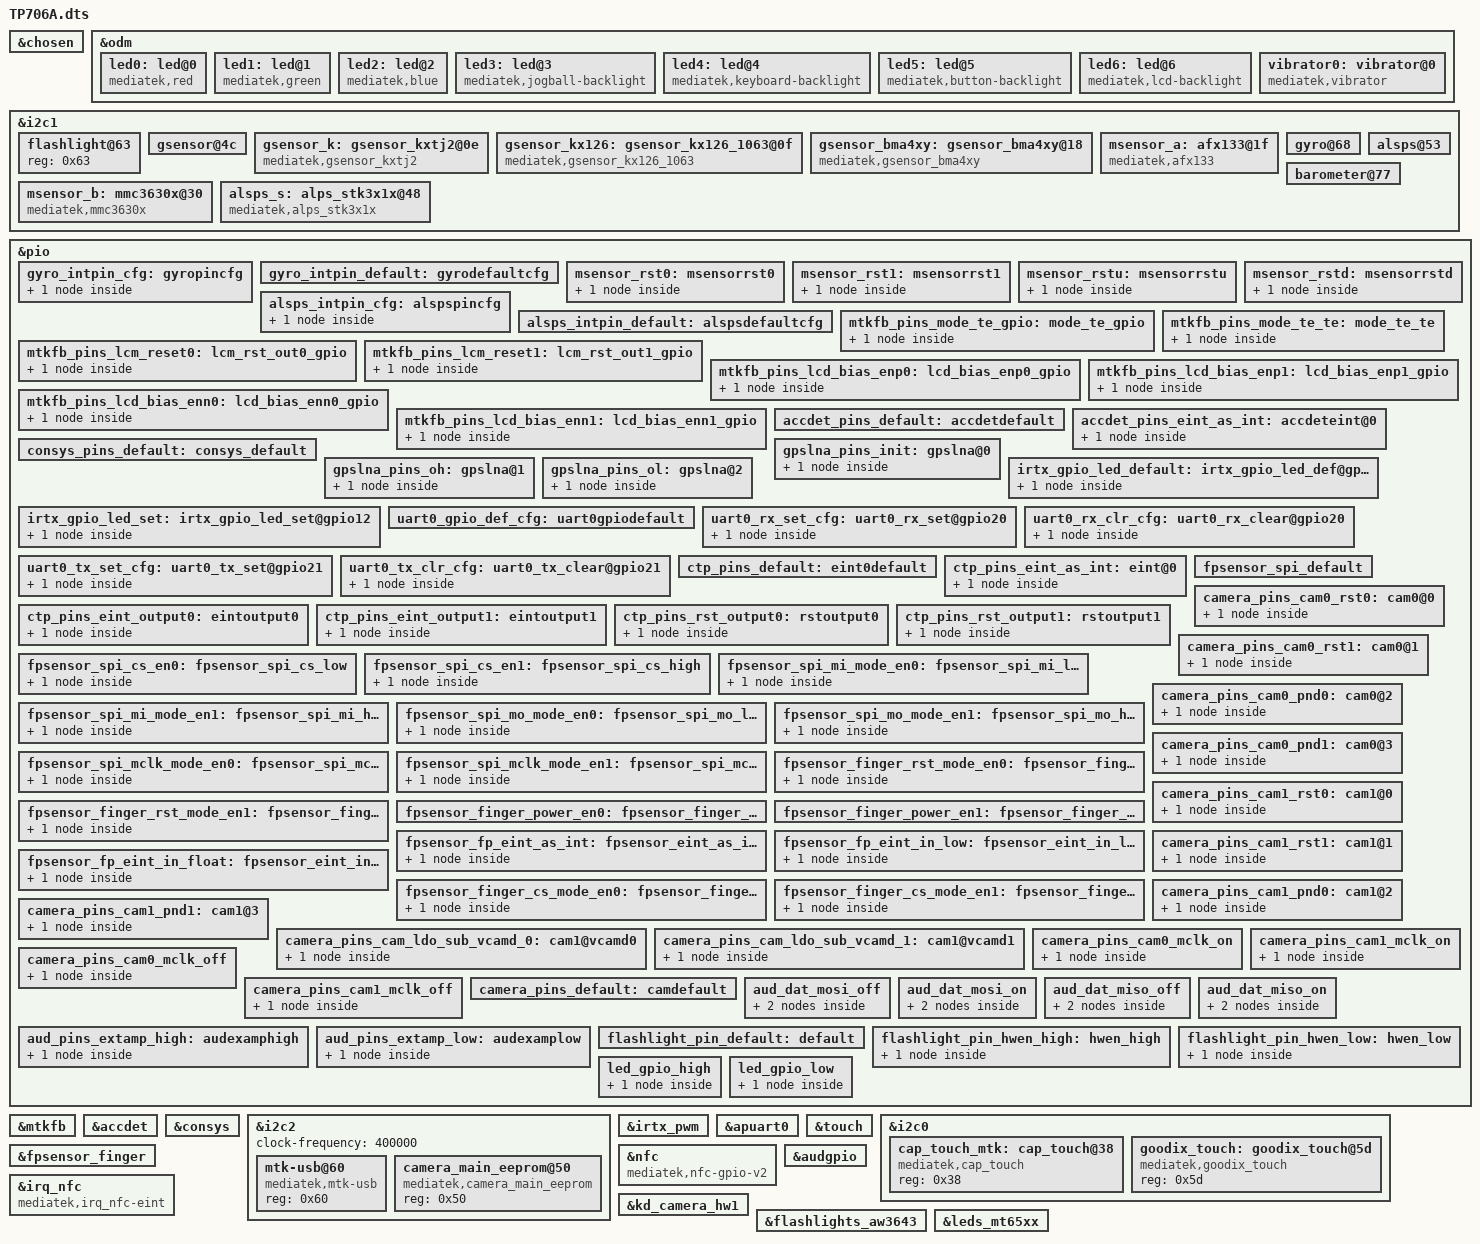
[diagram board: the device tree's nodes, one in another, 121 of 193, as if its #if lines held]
#include <generated/autoconf.h>
/dts-v1/;

#ifdef CONFIG_MTK_DTBO_FEATURE
/plugin/;
#include <dt-bindings/mmc/mt6739-msdc.h>
#include <dt-bindings/pinctrl/mt6739-pinfunc.h>
#else
#include "mt6739.dts"
#endif

#include <dt-bindings/interrupt-controller/irq.h>
#include <dt-bindings/interrupt-controller/arm-gic.h>

/*add by chipsailing*/
//#include "chips.dtsi"
#include "ChipSailing_pin.dtsi"
/*add end*/
/* chosen */
&chosen {
	bootargs = "console=tty0 console=ttyMT0,921600n1 root=/dev/ram initrd=0x44000000,\
0x1000000 loglevel=8 androidboot.selinux=permissive androidboot.hardware=mt6739 initcall_debug=1";
	/* fpga may has no lk, we need to specify display info here */
	/* fb buffer is reserved using this dts by memory node above */

	atag,videolfb-fb_base_l = <0x5e605000>;
	atag,videolfb-fb_base_h = <0>;
	atag,videolfb-islcmfound = <1>;
	atag,videolfb-islcm_inited = <0>;
	atag,videolfb-fps= <6000>;
	atag,videolfb-vramSize= <0x017bb000>;
	   atag,videolfb-lcmname= "ontim_ft8006u";	
/*atag,videolfb-lcmname= "txd_ili9881c";*/

};

&odm {
	led0:led@0 {
		compatible = "mediatek,red";
		led_mode = <2>;
		data = <1>;
		pwm_config = <0 0 0 0 0>;
	};
	led1:led@1 {
		compatible = "mediatek,green";
		led_mode = <3>;
		data = <2>;
		pwm_config = <0 0 0 0 0>;
	};
	led2:led@2 {
		compatible = "mediatek,blue";
		led_mode = <0>;
		data = <1>;
		pwm_config = <0 0 0 0 0>;
	};
	led3:led@3 {
		compatible = "mediatek,jogball-backlight";
		led_mode = <0>;
		data = <1>;
		pwm_config = <0 0 0 0 0>;
	};
	led4:led@4 {
		compatible = "mediatek,keyboard-backlight";
		led_mode = <0>;
		data = <1>;
		pwm_config = <0 0 0 0 0>;
	};
	led5:led@5 {
		compatible = "mediatek,button-backlight";
		led_mode = <0>;
		data = <1>;
		pwm_config = <0 0 0 0 0>;
	};
	led6:led@6 {
		compatible = "mediatek,lcd-backlight";
		led_mode = <4>;
		data = <1>;
		pwm_config = <0 2 0 0 0>;
	};
	vibrator0:vibrator@0 {
		compatible = "mediatek,vibrator";
		vib_timer = <25>;
		vib_limit = <9>;
		vib_vol= <9>;
	};
};

&i2c1 {
	flashlight@63 {
		reg = <0x63>;
		status = "okay";
	};

/*  start sensor */
	gsensor@4c {
		i2c_num	= <1>;
		i2c_addr = <0x4c 0 0 0>;
		direction = <6>;
		power_id = <0xffff>;
		power_vol = <0>;
		firlen = <16>;
		is_batch_supported = <1>;
	};

	gsensor_k:gsensor_kxtj2@0e {
		compatible = "mediatek,gsensor_kxtj2";
		reg = <0x0e>;
		status = "okay";
		
		i2c_num	= <1>;
		i2c_addr = <0x0e 0 0 0>;
		direction = <6>;
		power_id = <0xffff>;
		power_vol = <0>;
		firlen = <16>;
		is_batch_supported = <1>;
	};
	gsensor_kx126:gsensor_kx126_1063@0f {
		compatible = "mediatek,gsensor_kx126_1063";
		reg = <0x0f>;
		status = "okay";
		
		i2c_num	= <1>;
		i2c_addr = <0x0f 0 0 0>;
		direction = <6>;
		power_id = <0xffff>;
		power_vol = <0>;
		firlen = <16>;
		is_batch_supported = <1>;
	};
	gsensor_bma4xy:gsensor_bma4xy@18 {
		compatible = "mediatek,gsensor_bma4xy";
		reg = <0x18>;
		status = "okay";
		
		i2c_num	= <1>;
		i2c_addr = <0x18 0 0 0>;
		direction = <6>;
		power_id = <0xffff>;
		power_vol = <0>;
		firlen = <16>;
		is_batch_supported = <1>;
	};

	msensor_a:afx133@1f{
		compatible = "mediatek,afx133";
		reg = <0x1f>;
		i2c_num = <1>;
		i2c_addr = <0x1f 0x1d 0 0>;
		direction = <7>;
		power_id = <0xffff>;
		power_vol = <0>;
		is_batch_supported = <0>;
		pinctrl-names = "msensor_rst_out0", "msensor_rst_out1", "msensor_rst_in_pu", "msensor_rst_in_pd";
		pinctrl-0 = <&msensor_rst0>;
		pinctrl-1 = <&msensor_rst1>;
		pinctrl-2 = <&msensor_rstu>;
		pinctrl-3 = <&msensor_rstd>;
		status = "okay";
	};

	msensor_b:mmc3630x@30 {
		compatible = "mediatek,mmc3630x";
		reg = <0x30>;
		i2c_num = <1>;
		i2c_addr = <0x30 0 0 0>;
		direction = <7>;
		power_id = <0xffff>;
		power_vol = <0>;
		is_batch_supported = <0>;
		pinctrl-names = "msensor_rst_out0", "msensor_rst_out1", "msensor_rst_in_pu", "msensor_rst_in_pd";
		pinctrl-0 = <&msensor_rst0>;
		pinctrl-1 = <&msensor_rst1>;
		pinctrl-2 = <&msensor_rstu>;
		pinctrl-3 = <&msensor_rstd>;
		status = "okay";
	};

	gyro@68 {
		pinctrl-names = "pin_default", "pin_cfg";
		pinctrl-0 = <&gyro_intpin_default>;
		pinctrl-1 = <&gyro_intpin_cfg>;
		i2c_num = <1>;
		i2c_addr = <0x68 0 0 0>;
		direction = <5>;
		power_id = <0xffff>;
		power_vol = <0>;
		firlen = <0>;
		is_batch_supported = <0>;
	};

	alsps@53 {
		pinctrl-names = "pin_default", "pin_cfg";
		pinctrl-0 = <&alsps_intpin_default>;
		pinctrl-1 = <&alsps_intpin_cfg>;
		status = "okay";
		/* customization */

                /*compatible                              = "mediatek,ltr578";*/
		i2c_num = <1>;
              i2c_addr                                = <0x53 0 0 0>;
		polling_mode_ps = <0>;
		polling_mode_als = <1>;
		power_id = <0xffff>;
		power_vol = <0>;
                als_level = <
                                        0  119  275  455  896  1507  2116    2661
                                        0  133  304   502  1004  2005  3058 4000
                                        0  133  304   502  1004  2005  3058 4000
                                        0  85  194  320  630  1059  1667    2210
                                        0  133  304   502  1004  2005  3058 4000
                                        0  133  304   502  1004  2005  3058 4000
                                         >;
                als_value = < 0  133  304  502   1004  2005  3058   4000 >;
                ps_threshold_high               =  <1000>;
                ps_threshold_low                =  <800>;
		is_batch_supported_ps = <0>;
		is_batch_supported_als = <0>;
		/*
		als_calib_enable = <1>;
                als_ch0_expect               =  <1000>;
                als_ch1_expect                =  <800>;
		*/
	};

	alsps_s:alps_stk3x1x@48 {
		compatible				= "mediatek,alps_stk3x1x";
		reg = <0x48>;
		status = "okay";

		pinctrl-names = "pin_default", "pin_cfg";
		pinctrl-0 = <&alsps_intpin_default>;
		pinctrl-1 = <&alsps_intpin_cfg>;

		interrupt-parent = <&pio>;
		interrupts = <1 IRQ_TYPE_LEVEL_LOW 1 0>;

		i2c_num				= <1>;
		i2c_addr				= <0x48 0 0 0>;
		polling_mode_ps			= <0>;
		polling_mode_als		= <1>;
		power_id				= <0xffff>;
		power_vol				= <0>;
		als_level = < 
					0  39   91    150    290    505     736    943
					0  82   174   299    582    1319    2940  3333
					0  123   264   399    627    1444   2144   2800
					0  63   144    237    445    724     991    1231
					0  72   163   258    560    1576   2400   3152
					0  112   240   475    746    1719   2552   3333
					  >;
		als_value = < 0  133  304  502   1004  2005  3058   4000 >;
		state_val		=  <0>;
		psctrl_val		=  <0x31>;
		alsctrl_val	= <0x38>;
		ledctrl_val	= <0xFF>;
		wait_val		= <0xF>;
		ps_threshold_high		=  <1700>;
		ps_threshold_low		=  <1500>;
		is_batch_supported_ps	= <0>;
		is_batch_supported_als	= <0>;
		/*
                als_calib_enable = <1>;
                als_ch0_expect               =  <1000>;
                als_ch1_expect                =  <800>;
                */
		};

	barometer@77 {
		i2c_num = <1>;
		i2c_addr = <0x77 0 0 0>;
		direction = <0>;
		power_id = <0xffff>;
		power_vol = <0>;
		firlen = <32>;
		is_batch_supported = <0>;
	};
/* end sensor */
};

/* sensor gpio standization */
&pio {

	gyro_intpin_cfg: gyropincfg {

	    pins_cmd_dat {
			pins = <PINMUX_GPIO5__FUNC_GPIO5>;
			slew-rate = <0>;
			bias-pull-down = <00>;
		};
	};

	gyro_intpin_default: gyrodefaultcfg {

	};
};
&pio {

	msensor_rst0: msensorrst0 {
	    pins_cmd_dat {
			pins = <PINMUX_GPIO26__FUNC_GPIO26>;
			slew-rate = <1>;
			output-low;
		};
	};

	msensor_rst1: msensorrst1 {
	    pins_cmd_dat {
			pins = <PINMUX_GPIO26__FUNC_GPIO26>;
			slew-rate = <1>;
			output-high;
		};
	};

	msensor_rstu: msensorrstu {
	    pins_cmd_dat {
			pins = <PINMUX_GPIO26__FUNC_GPIO26>;
			slew-rate = <0>;
			bias-pull-up = <00>;
		};
	};

	msensor_rstd: msensorrstd {
	    pins_cmd_dat {
			pins = <PINMUX_GPIO26__FUNC_GPIO26>;
			slew-rate = <0>;
			bias-pull-down = <00>;
		};
	};

};

&pio {
	alsps_intpin_cfg: alspspincfg {

		pins_cmd_dat {
			pins = <PINMUX_GPIO1__FUNC_GPIO1>;
			slew-rate = <0>;
			bias-pull-up = <MTK_PUPD_SET_R1R0_01>;
		};
	};

	alsps_intpin_default: alspsdefaultcfg {

	};
};

/* sensor end */

/* DISPSYS GPIO standardization */
&pio {
	mtkfb_pins_mode_te_gpio: mode_te_gpio {
		pins_cmd_dat {
			pins = <PINMUX_GPIO84__FUNC_DSI_TE>;
		};
	};

	mtkfb_pins_mode_te_te: mode_te_te {
		pins_cmd_dat {
			pins = <PINMUX_GPIO84__FUNC_DSI_TE>;
		};
	};

	mtkfb_pins_lcm_reset0: lcm_rst_out0_gpio {
		pins_cmd_dat {
			pins = <PINMUX_GPIO83__FUNC_GPIO83>;
			slew-rate = <1>;
			output-low;
		};
	};

	mtkfb_pins_lcm_reset1: lcm_rst_out1_gpio {
		pins_cmd_dat {
			pins = <PINMUX_GPIO83__FUNC_GPIO83>;
			slew-rate = <1>;
			output-high;
		};
	};

	mtkfb_pins_lcd_bias_enp0: lcd_bias_enp0_gpio {
		pins_cmd_dat {
			pins = <PINMUX_GPIO122__FUNC_GPIO122>;
			slew-rate = <1>;
			output-low;
		};
	};
	mtkfb_pins_lcd_bias_enp1: lcd_bias_enp1_gpio {
		pins_cmd_dat {
			pins = <PINMUX_GPIO122__FUNC_GPIO122>;
			slew-rate = <1>;
			output-high;
		};
	};

	mtkfb_pins_lcd_bias_enn0: lcd_bias_enn0_gpio {
		pins_cmd_dat {
			pins = <PINMUX_GPIO112__FUNC_GPIO112>;
			slew-rate = <1>;
			output-low;
		};
	};
	mtkfb_pins_lcd_bias_enn1: lcd_bias_enn1_gpio {
		pins_cmd_dat {
			pins = <PINMUX_GPIO112__FUNC_GPIO112>;
			slew-rate = <1>;
			output-high;
		};
	};

};

&mtkfb {
	pinctrl-names = "mode_te_gpio", "mode_te_te", "lcm_rst_out0_gpio",
		"lcm_rst_out1_gpio", "lcd_bias_enp0_gpio", "lcd_bias_enp1_gpio", "lcd_bias_enn0_gpio", "lcd_bias_enn1_gpio";
	pinctrl-0 = <&mtkfb_pins_mode_te_gpio>;
	pinctrl-1 = <&mtkfb_pins_mode_te_te>;
	pinctrl-2 = <&mtkfb_pins_lcm_reset0>;
	pinctrl-3 = <&mtkfb_pins_lcm_reset1>;
	pinctrl-4 = <&mtkfb_pins_lcd_bias_enp0>;
	pinctrl-5 = <&mtkfb_pins_lcd_bias_enp1>;
	pinctrl-6 = <&mtkfb_pins_lcd_bias_enn0>;
	pinctrl-7 = <&mtkfb_pins_lcd_bias_enn1>;
	status = "okay";
};
/* DISPSYS GPIO standardization end */


/* accdet start */
&accdet {
	/* accdet micbias voltage: 0x07,2.7v;0x05,2.5v;0x02,1.9v */
	accdet-mic-vol = <6>;
	headset-mode-setting = <0x500 0x500 1 0x1f0 0x800 0x800 0x20 0x44>;
	accdet-plugout-debounce = <1>;
	/*1:ACC mode, 2:low cost without in bias, 6:low cost with in bias*/
    /* [wuhefeng] change mic-mode to 1(ACC MODE) */
	accdet-mic-mode = <1>;
	/* eint_level_trigger: 8,LEVEL_LOW(default);4,LEVEL_HIGH;others,LEVEL_LOW */
	headset-eint-level-pol = <8>;
	/*0--MD_MAX--UP_MAX--DW_MAX*/
	headset-three-key-threshold = <0 80 220 400>;
	headset-three-key-threshold-CDD = <0 121 192 600>;
	/*0--MD_MAX--VOICE_MAX--UP_MAX--DW_MAX*/
	headset-four-key-threshold = <0 58 121 192 400>;
	/* ACCDET GPIO standardization ACC mode no use */
	pinctrl-names = "default", "state_eint_as_int";
	pinctrl-0 = <&accdet_pins_default>;
	pinctrl-1 = <&accdet_pins_eint_as_int>;
	status = "okay";
};
&pio {
	accdet_pins_default: accdetdefault {
	};
	accdet_pins_eint_as_int: accdeteint@0 {
		pins_cmd_dat {
			/*pins = <PINMUX_GPIO11__FUNC_GPIO11>;*/
			slew-rate = <0>;
			bias-disable;
		};
	};
};
/* accdet end */
/* CONSYS GPIO standardization */
&pio {
	consys_pins_default: consys_default {
	};
	gpslna_pins_init: gpslna@0 {
		pins_cmd_dat {
			pins = <PINMUX_GPIO118__FUNC_GPIO118>;
			slew-rate = <0>;
			bias-disable;
			output-low;
		};
	};
	gpslna_pins_oh: gpslna@1 {
		pins_cmd_dat {
			pins = <PINMUX_GPIO118__FUNC_GPIO118>;
			slew-rate = <1>;
			output-high;
		};
	};
	gpslna_pins_ol: gpslna@2 {
		pins_cmd_dat {
			pins = <PINMUX_GPIO118__FUNC_GPIO118>;
			slew-rate = <1>;
			output-low;
		};
	};
};
&consys {
	pinctrl-names = "default", "gps_lna_state_init", "gps_lna_state_oh", "gps_lna_state_ol";
	pinctrl-0 = <&consys_pins_default>;
	pinctrl-1 = <&gpslna_pins_init>;
	pinctrl-2 = <&gpslna_pins_oh>;
	pinctrl-3 = <&gpslna_pins_ol>;
	status = "okay";
};
&i2c2 {
	#address-cells = <1>;
	#size-cells = <0>;
	clock-frequency = <400000>;

	mtk-usb@60 {
		compatible = "mediatek,mtk-usb";
		reg = <0x60>;
		status = "okay";
	};
    
	camera_main_eeprom@50 {
		compatible = "mediatek,camera_main_eeprom";
		reg = <0x50>;
	};
};

/* IRTX GPIO Start */
&irtx_pwm {
	pinctrl-names = "irtx_gpio_led_default", "irtx_gpio_led_set";
	pinctrl-0 = <&irtx_gpio_led_default>;
	pinctrl-1 = <&irtx_gpio_led_set>;
	status = "okay";
};
&pio {
	/* IRTX GPIO Settings -Start */
	/* default: GPIO0, output, high */
	irtx_gpio_led_default:irtx_gpio_led_def@gpio12 {
		pins_cmd_dat {
			pins = <PINMUX_GPIO12__FUNC_GPIO12>;
			slew-rate = <1>;
			bias-disable;
			output-low;
			input-schmitt-enable = <0>;
		};
	};

	irtx_gpio_led_set:irtx_gpio_led_set@gpio12 {
		pins_cmd_dat {
			pins = <PINMUX_GPIO12__FUNC_PWM1>;
			slew-rate = <1>;
			output-high;
		};
	};
}; /* IRTX GPIO Settings -End */

/* UART GPIO */
&apuart0 {
	pinctrl-names = "uart0_gpio_default",
			"uart0_rx_set",
			"uart0_rx_clear",
			"uart0_tx_set",
			"uart0_tx_clear";
	pinctrl-0 = <&uart0_gpio_def_cfg>;
	pinctrl-1 = <&uart0_rx_set_cfg>;
	pinctrl-2 = <&uart0_rx_clr_cfg>;
	pinctrl-3 = <&uart0_tx_set_cfg>;
	pinctrl-4 = <&uart0_tx_clr_cfg>;
	status = "okay";
};

&pio {
	/* UART GPIO Settings - Start */
	/* UART0: rx set, rx clear, tx clear, tx clear*/
	uart0_gpio_def_cfg:uart0gpiodefault {

	};
	uart0_rx_set_cfg:uart0_rx_set@gpio20 {
		pins_cmd_dat {
			pins = <PINMUX_GPIO20__FUNC_UART0RX>;
		};
	};
	uart0_rx_clr_cfg:uart0_rx_clear@gpio20 {
		pins_cmd_dat {
			pins = <PINMUX_GPIO20__FUNC_GPIO20>;
			slew-rate = <1>;
			output-high;
		};
	};
	uart0_tx_set_cfg:uart0_tx_set@gpio21 {
		pins_cmd_dat {
			pins = <PINMUX_GPIO21__FUNC_UART0TX>;
		};
	};
	uart0_tx_clr_cfg:uart0_tx_clear@gpio21 {
		pins_cmd_dat {
			pins = <PINMUX_GPIO21__FUNC_GPIO21>;
			slew-rate = <1>;
			output-high;
		};
	};
};/* UART GPIO end */

/* TOUCH start */
&touch {
	tpd-resolution = <720 1440>;
	use-tpd-button = <0>;
	tpd-key-num = <3>;
	tpd-key-local= <139 172 158 0>;
	tpd-key-dim-local = <90 883 100 40 230 883 100 40 370 883 100 40 0 0 0 0>;
	tpd-max-touch-num = <5>;
	tpd-filter-enable = <0>;
	tpd-filter-pixel-density = <106>;
	tpd-filter-custom-prameters = <0 0 0 0 0 0 0 0 0 0 0 0>;
	tpd-filter-custom-speed = <0 0 0>;
	pinctrl-names = "default", "state_eint_as_int", "state_eint_output0", "state_eint_output1",
		"state_rst_output0", "state_rst_output1";
	pinctrl-0 = <&ctp_pins_default>;
	pinctrl-1 = <&ctp_pins_eint_as_int>;
	pinctrl-2 = <&ctp_pins_eint_output0>;
	pinctrl-3 = <&ctp_pins_eint_output1>;
	pinctrl-4 = <&ctp_pins_rst_output0>;
	pinctrl-5 = <&ctp_pins_rst_output1>;
	status = "okay";
};
&i2c0 {
	cap_touch_mtk:cap_touch@38 {
		compatible = "mediatek,cap_touch";
		reg = <0x38>;
		status = "okay";
	};

    goodix_touch:goodix_touch@5d {
        compatible = "mediatek,goodix_touch";
        reg = <0x5d>;
        status = "okay";
    };

};
&pio {
	ctp_pins_default: eint0default {
	};
	ctp_pins_eint_as_int: eint@0 {
		pins_cmd_dat {
			pins = <PINMUX_GPIO6__FUNC_GPIO6>;
			slew-rate = <0>;
			bias-disable;
		};
	};
	ctp_pins_eint_output0: eintoutput0 {
		pins_cmd_dat {
			pins = <PINMUX_GPIO6__FUNC_GPIO6>;
			slew-rate = <1>;
			output-low;
		};
	};
	ctp_pins_eint_output1: eintoutput1 {
		pins_cmd_dat {
			pins = <PINMUX_GPIO6__FUNC_GPIO6>;
			slew-rate = <1>;
			output-high;
		};
	};
	ctp_pins_rst_output0: rstoutput0 {
		pins_cmd_dat {
			pins = <PINMUX_GPIO119__FUNC_GPIO119>;
			slew-rate = <1>;
			output-low;
		};
	};
	ctp_pins_rst_output1: rstoutput1 {
		pins_cmd_dat {
			pins = <PINMUX_GPIO119__FUNC_GPIO119>;
			slew-rate = <1>;
			output-high;
		};
	};
};
/* TOUCH end */

/* FPSENSOR start */
&pio {

	fpsensor_spi_default: fpsensor_spi_default {
	};

	fpsensor_spi_cs_en0: fpsensor_spi_cs_low {
		pins_cmd_dat {
			pins = <PINMUX_GPIO31__FUNC_SPI0_A_CSB>;
			slew-rate = <1>;
			output-low;
		};
	};
	fpsensor_spi_cs_en1: fpsensor_spi_cs_high {
		pins_cmd_dat {
			pins = <PINMUX_GPIO31__FUNC_SPI0_A_CSB>;
			slew-rate = <1>;
			output-high;
		};
	};	
	fpsensor_spi_mi_mode_en0: fpsensor_spi_mi_low {
		pins_cmd_dat {
			pins = <PINMUX_GPIO33__FUNC_SPI0_A_MI>;
			slew-rate = <0>;
			bias-pull-up = <00>;
		};
	};
	fpsensor_spi_mi_mode_en1: fpsensor_spi_mi_high {
		pins_cmd_dat {
			pins = <PINMUX_GPIO33__FUNC_SPI0_A_MI>;
			bias-disable;
		};
	};	
	fpsensor_spi_mo_mode_en0: fpsensor_spi_mo_low {
		pins_cmd_dat {
			pins = <PINMUX_GPIO34__FUNC_SPI0_A_MO>;
			slew-rate = <1>;
			output-low;
		};
	};
	fpsensor_spi_mo_mode_en1: fpsensor_spi_mo_high {
		pins_cmd_dat {
			pins = <PINMUX_GPIO34__FUNC_SPI0_A_MO>;
			slew-rate = <1>;
			output-high;
		};
	};	
		fpsensor_spi_mclk_mode_en0: fpsensor_spi_mclk_low {
		pins_cmd_dat {
			pins = <PINMUX_GPIO32__FUNC_SPI0_A_CLK>;
			slew-rate = <1>;
			output-low;
		};
	};
	fpsensor_spi_mclk_mode_en1: fpsensor_spi_mclk_high {
		pins_cmd_dat {
			pins = <PINMUX_GPIO32__FUNC_SPI0_A_CLK>;
			slew-rate = <1>;
			output-high;
		};
	};	
	fpsensor_finger_rst_mode_en0: fpsensor_finger_rst_low {
		pins_cmd_dat {
			pins = <PINMUX_GPIO52__FUNC_GPIO52>;
			slew-rate = <1>;
			output-low; 
		};
	};
	fpsensor_finger_rst_mode_en1: fpsensor_finger_rst_high {
		pins_cmd_dat {
			pins = <PINMUX_GPIO52__FUNC_GPIO52>;
			slew-rate = <1>;
			output-high;
		};
	};	
	fpsensor_finger_power_en0: fpsensor_finger_power_low {
	
	};
	fpsensor_finger_power_en1: fpsensor_finger_power_high {
		
	};	
	fpsensor_fp_eint_as_int: fpsensor_eint_as_int {
		pins_cmd_dat {
			pins = <PINMUX_GPIO0__FUNC_GPIO0>;
			slew-rate = <0>;
			bias-disable;
		};
	};
	fpsensor_fp_eint_in_low: fpsensor_eint_in_low {
		pins_cmd_dat {
			pins = <PINMUX_GPIO0__FUNC_GPIO0>;
			slew-rate = <0>;
			bias-pull-down = <00>;
		};
	};
	fpsensor_fp_eint_in_float: fpsensor_eint_in_float {
		pins_cmd_dat {
			pins = <PINMUX_GPIO0__FUNC_GPIO0>;
			slew-rate = <0>;
			bias-disable;
		};
	};
	fpsensor_finger_cs_mode_en0: fpsensor_finger_cs_low {
		pins_cmd_dat {
			pins = <PINMUX_GPIO31__FUNC_GPIO31>;
			slew-rate = <1>;
			output-low;
			input-schmitt-enable = <0>;
		};
	};
	fpsensor_finger_cs_mode_en1: fpsensor_finger_cs_high {
		pins_cmd_dat {
			pins = <PINMUX_GPIO31__FUNC_GPIO31>;
			slew-rate = <1>;
			output-high;
			input-schmitt-enable = <0>;
		};
	};	
};

&fpsensor_finger {
	interrupt-parent = <&pio>;
	interrupts = <0 IRQ_TYPE_EDGE_RISING 1 0>;
	debounce = <2 0>;
	pinctrl-names = "fpsensor_spi_default", "fpsensor_spi_cs_low","fpsensor_spi_cs_high","fpsensor_spi_mi_low","fpsensor_spi_mi_high",
					"fpsensor_spi_mo_low","fpsensor_spi_mo_high","fpsensor_spi_mclk_low","fpsensor_spi_mclk_high",
					"fpsensor_finger_rst_low","fpsensor_finger_rst_high","fpsensor_finger_power_low","fpsensor_finger_power_high",
					"fpsensor_eint","fpsensor_eint_in_low","fpsensor_eint_in_float","fpsensor_finger_cs_low","fpsensor_finger_cs_high";
	pinctrl-0 = <&fpsensor_spi_default>;
	pinctrl-1 = <&fpsensor_spi_cs_en0>;
	pinctrl-2 = <&fpsensor_spi_cs_en1>;
	pinctrl-3 = <&fpsensor_spi_mi_mode_en0>;
	pinctrl-4 = <&fpsensor_spi_mi_mode_en1>;
	pinctrl-5 = <&fpsensor_spi_mo_mode_en0>;
	pinctrl-6 = <&fpsensor_spi_mo_mode_en1>;
	pinctrl-7 = <&fpsensor_spi_mclk_mode_en0>;
	pinctrl-8 = <&fpsensor_spi_mclk_mode_en1>;	
	pinctrl-9 = <&fpsensor_finger_rst_mode_en0>;
	pinctrl-10 = <&fpsensor_finger_rst_mode_en1>;
	pinctrl-11 = <&fpsensor_finger_power_en0>;
	pinctrl-12 = <&fpsensor_finger_power_en1>;	
	pinctrl-13 = <&fpsensor_fp_eint_as_int>;
	pinctrl-14 = <&fpsensor_fp_eint_in_low>;
	pinctrl-15 = <&fpsensor_fp_eint_in_float>;
	pinctrl-16 = <&fpsensor_finger_cs_mode_en0>;
	pinctrl-17 = <&fpsensor_finger_cs_mode_en1>;
	status = "okay";
};
/* FPSENSOR end */

/* NFC start */
&nfc {
	compatible = "mediatek,nfc-gpio-v2";
	gpio-rst = <7>;
	gpio-rst-std = <&pio 7 0x0>;
	gpio-irq = <14>;
	gpio-irq-std = <&pio 14 0x0>;
};

&irq_nfc {
	compatible = "mediatek,irq_nfc-eint";
};
/* NFC end */

/* CAMERA GPIO standardization */
&pio {
	camera_pins_cam0_rst0: cam0@0 {
		pins_cmd_dat {
			pins = <PINMUX_GPIO29__FUNC_GPIO29>;
			slew-rate = <1>; /*direction 0:in, 1:out*/
			output-low;/*direction out used only. output_low or high*/
		};
	};
	camera_pins_cam0_rst1: cam0@1 {
		pins_cmd_dat {
			pins = <PINMUX_GPIO29__FUNC_GPIO29>;
			slew-rate = <1>;
			output-high;
		};
	};
	camera_pins_cam0_pnd0: cam0@2 {
		pins_cmd_dat {
			pins = <PINMUX_GPIO30__FUNC_GPIO30>;
			slew-rate = <1>;
			output-low;
		};
	};
	camera_pins_cam0_pnd1: cam0@3 {
		pins_cmd_dat {
			pins = <PINMUX_GPIO30__FUNC_GPIO30>;
			slew-rate = <1>;
			output-high;
		};
	};
	camera_pins_cam1_rst0: cam1@0 {
		pins_cmd_dat {
			pins = <PINMUX_GPIO22__FUNC_GPIO22>;
			slew-rate = <1>; /*direction 0:in, 1:out*/
			output-low;/*direction out used only. output_low or high*/
		};
	};
	camera_pins_cam1_rst1: cam1@1 {
		pins_cmd_dat {
			pins = <PINMUX_GPIO22__FUNC_GPIO22>;
			slew-rate = <1>;
			output-high;
		};
	};
	camera_pins_cam1_pnd0: cam1@2 {
		pins_cmd_dat {
			pins = <PINMUX_GPIO23__FUNC_GPIO23>;
			slew-rate = <1>;
			output-low;
		};
	};
	camera_pins_cam1_pnd1: cam1@3 {
		pins_cmd_dat {
			pins = <PINMUX_GPIO23__FUNC_GPIO23>;
			slew-rate = <1>;
			output-high;
		};
	};
	camera_pins_cam_ldo_sub_vcamd_0: cam1@vcamd0 {
		pins_cmd_dat {
			pins = <PINMUX_GPIO9__FUNC_GPIO9>;
			slew-rate = <1>;
			output-low;
		};
	};
	camera_pins_cam_ldo_sub_vcamd_1: cam1@vcamd1 {
		pins_cmd_dat {
			pins = <PINMUX_GPIO9__FUNC_GPIO9>;
			slew-rate = <1>;
			output-high;
		};
	};
	camera_pins_cam0_mclk_on: camera_pins_cam0_mclk_on {
		pins_cmd_dat {
			pins = <PINMUX_GPIO126__FUNC_CMMCLK0>;
		};
	};
	camera_pins_cam0_mclk_off: camera_pins_cam0_mclk_off {
		pins_cmd_dat {
			pins = <PINMUX_GPIO126__FUNC_GPIO126>;
		};
	};
	camera_pins_cam1_mclk_on: camera_pins_cam1_mclk_on {
		pins_cmd_dat {
			pins = <PINMUX_GPIO126__FUNC_CMMCLK0>;
		};
	};
	camera_pins_cam1_mclk_off: camera_pins_cam1_mclk_off {
		pins_cmd_dat {
			pins = <PINMUX_GPIO126__FUNC_GPIO126>;
		};
	};
	camera_pins_default: camdefault {
	};
};

&kd_camera_hw1 {
	pinctrl-names = "default",
			"cam0_rst0", "cam0_rst1", "cam0_pnd0", "cam0_pnd1",
			"cam1_rst0", "cam1_rst1", "cam1_pnd0", "cam1_pnd1",
			"cam_ldo_sub_vcamd_0", "cam_ldo_sub_vcamd_1",
			"cam0_mclk_on", "cam0_mclk_off",
			"cam1_mclk_on", "cam1_mclk_off";

	pinctrl-0 = <&camera_pins_default>;
	pinctrl-1 = <&camera_pins_cam0_rst0>;
	pinctrl-2 = <&camera_pins_cam0_rst1>;
	pinctrl-3 = <&camera_pins_cam0_pnd0>;
	pinctrl-4 = <&camera_pins_cam0_pnd1>;
	pinctrl-5 = <&camera_pins_cam1_rst0>;
	pinctrl-6 = <&camera_pins_cam1_rst1>;
	pinctrl-7 = <&camera_pins_cam1_pnd0>;
	pinctrl-8 = <&camera_pins_cam1_pnd1>;
	pinctrl-9 = <&camera_pins_cam_ldo_sub_vcamd_0>;
	pinctrl-10 = <&camera_pins_cam_ldo_sub_vcamd_1>;
	pinctrl-11 = <&camera_pins_cam0_mclk_on>;
	pinctrl-12 = <&camera_pins_cam0_mclk_off>;
	pinctrl-13 = <&camera_pins_cam1_mclk_on>;
	pinctrl-14 = <&camera_pins_cam1_mclk_off>;
	status = "okay";

};
/* CAMERA GPIO end */

/* AUDIO GPIO standardization */
&audgpio {
	pinctrl-names = "aud_dat_mosi_off",
			"aud_dat_mosi_on",
			"aud_dat_miso_off",
			"aud_dat_miso_on",
			"extamp-pullhigh",
			"extamp-pulllow";
	pinctrl-0 = <&aud_dat_mosi_off>;
	pinctrl-1 = <&aud_dat_mosi_on>;
	pinctrl-2 = <&aud_dat_miso_off>;
	pinctrl-3 = <&aud_dat_miso_on>;
	pinctrl-4 = <&aud_pins_extamp_high>;
	pinctrl-5 = <&aud_pins_extamp_low>;
	status = "okay";
};

&pio {
	aud_dat_mosi_off: aud_dat_mosi_off {
		pins_cmd1_dat {
			pins = <PINMUX_GPIO63__FUNC_GPIO63>;
			input-enable;
			slew-rate = <0>;
			bias-disable;
		};
		pins_cmd2_dat {
			pins = <PINMUX_GPIO64__FUNC_GPIO64>;
			input-enable;
			slew-rate = <0>;
			bias-disable;
		};
	};

	aud_dat_mosi_on: aud_dat_mosi_on {
		pins_cmd1_dat {
			pins = <PINMUX_GPIO63__FUNC_AUD_DAT_MOSI0>;
		};
		pins_cmd2_dat {
			pins = <PINMUX_GPIO64__FUNC_AUD_DAT_MOSI1>;
		};
	};

	aud_dat_miso_off: aud_dat_miso_off {
		pins_cmd1_dat {
			pins = <PINMUX_GPIO67__FUNC_GPIO67>;
			input-enable;
			slew-rate = <0>;
			bias-disable;
		};
		pins_cmd2_dat {
			pins = <PINMUX_GPIO68__FUNC_GPIO68>;
			input-enable;
			slew-rate = <0>;
			bias-disable;
		};
	};

	aud_dat_miso_on: aud_dat_miso_on {
		pins_cmd1_dat {
			pins = <PINMUX_GPIO67__FUNC_AUD_DAT_MISO0>;
		};
		pins_cmd2_dat {
			pins = <PINMUX_GPIO68__FUNC_AUD_DAT_MISO1>;
		};
	};
	aud_pins_extamp_high: audexamphigh {
		pins_cmd_dat {
			pins = <PINMUX_GPIO24__FUNC_GPIO24>;
			slew-rate = <1>;
			output-high;
		};
	};

	aud_pins_extamp_low: audexamplow {
		pins_cmd_dat {
			pins = <PINMUX_GPIO24__FUNC_GPIO24>;
			slew-rate = <1>;
			output-low;
		};
	};

};
/* AUDIO end */

/* flashlight begin */

&pio{
    flashlight_pin_default: default{};

    flashlight_pin_hwen_high: hwen_high{
		pins_cmd_dat {
			pins = <PINMUX_GPIO10__FUNC_GPIO10>;
			slew-rate = <1>;
			output-high;
		};
	};
	
    flashlight_pin_hwen_low: hwen_low{
		pins_cmd_dat{
			pins = <PINMUX_GPIO10__FUNC_GPIO10>;
			slew-rate = <1>;
			output-low;
		};
	};
    
};

&flashlights_aw3643{
    pinctrl-names = "default", "hwen_high", "hwen_low";
    pinctrl-0 = <&flashlight_pin_default>;
    pinctrl-1 = <&flashlight_pin_hwen_high>;
    pinctrl-2 = <&flashlight_pin_hwen_low>;
    status = "okay";
};

/* flashlight end */

&pio {


		led_gpio_high: led_gpio_high {
			pins_cmd_dat {
				pins = <PINMUX_GPIO94__FUNC_GPIO94>;
				slew-rate = <1>;
				output-high;
			};
		};

		led_gpio_low: led_gpio_low {
			pins_cmd_dat {
				pins = <PINMUX_GPIO94__FUNC_GPIO94>;
				slew-rate = <1>;
				output-low;
			};
		};

};


	&leds_mt65xx {
		pinctrl-names = "led_gpio_high",
				          "led_gpio_low";
		pinctrl-0 = <&led_gpio_high>;
		pinctrl-1 = <&led_gpio_low>;
		status = "okay";
      };


#include <k39tv1_bsp/cust.dtsi>
/*End of this file, DO NOT ADD ANYTHING HERE*/
